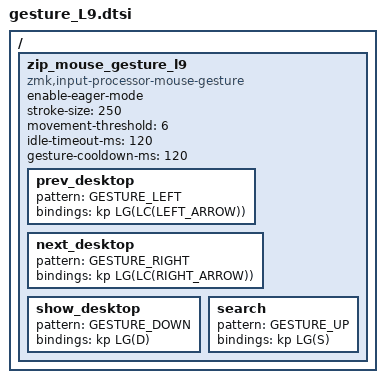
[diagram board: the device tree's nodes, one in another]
#include <dt-bindings/zmk/keys.h>

 / {
  zip_mouse_gesture_l9: zip_mouse_gesture_l9 {
    compatible = "zmk,input-processor-mouse-gesture";
    #input-processor-cells = <0>;

    enable-eager-mode;
    stroke-size = <250>;
    movement-threshold = <6>;
    idle-timeout-ms = <120>;
    gesture-cooldown-ms = <120>;

    /* 例: デスクトップ切替 */
    prev_desktop { pattern = <GESTURE_LEFT>;  bindings = <&kp LG(LC(LEFT_ARROW))>; };
    next_desktop { pattern = <GESTURE_RIGHT>; bindings = <&kp LG(LC(RIGHT_ARROW))>; };
    show_desktop { pattern = <GESTURE_DOWN>;  bindings = <&kp LG(D)>; };
    search       { pattern = <GESTURE_UP>;    bindings = <&kp LG(S)>; };
  };
};
